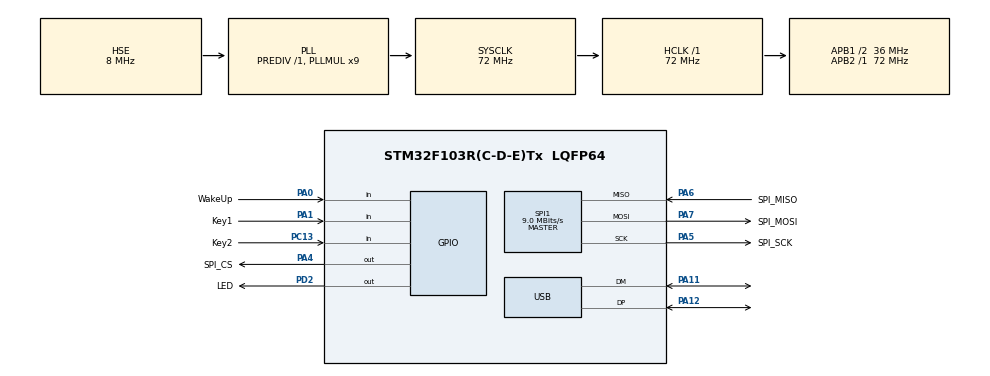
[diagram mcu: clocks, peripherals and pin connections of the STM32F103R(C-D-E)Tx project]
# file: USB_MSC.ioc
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Mcu.Family=STM32F1
Mcu.Name=STM32F103R(C-D-E)Tx
Mcu.Package=LQFP64
NVIC.PriorityGroup=NVIC_PRIORITYGROUP_4
NVIC.TIM6_IRQn=true\:1\:0\:true\:false\:true\:true\:true\:true
NVIC.USB_LP_CAN1_RX0_IRQn=true\:0\:0\:false\:false\:true\:false\:true\:true
PA0-WKUP.GPIO_Label=WakeUp
PA0-WKUP.GPIO_PuPd=GPIO_PULLDOWN
PA0-WKUP.Signal=GPIO_Input
PA1.GPIO_Label=Key1
PA1.GPIO_PuPd=GPIO_PULLUP
PA1.Signal=GPIO_Input
PA11.Mode=Device
PA11.Signal=USB_DM
PA12.Mode=Device
PA12.Signal=USB_DP
PA13.Mode=Serial_Wire
PA13.Signal=SYS_JTMS-SWDIO
PA14.Mode=Serial_Wire
PA14.Signal=SYS_JTCK-SWCLK
PA4.GPIO_Label=SPI_CS
PA4.GPIO_PuPd=GPIO_PULLUP
PA4.GPIO_Speed=GPIO_SPEED_FREQ_HIGH
PA4.PinState=GPIO_PIN_SET
PA4.Signal=GPIO_Output
PA5.GPIO_Label=SPI_SCK
PA5.Mode=Full_Duplex_Master
PA5.Signal=SPI1_SCK
PA6.GPIO_Label=SPI_MISO
PA6.Mode=Full_Duplex_Master
PA6.Signal=SPI1_MISO
PA7.GPIO_Label=SPI_MOSI
PA7.Mode=Full_Duplex_Master
PA7.Signal=SPI1_MOSI
PC13-TAMPER-RTC.GPIO_Label=Key2
PC13-TAMPER-RTC.GPIO_PuPd=GPIO_PULLUP
PC13-TAMPER-RTC.Signal=GPIO_Input
PD0-OSC_IN.Mode=HSE-External-Oscillator
PD0-OSC_IN.Signal=RCC_OSC_IN
PD1-OSC_OUT.Mode=HSE-External-Oscillator
PD1-OSC_OUT.Signal=RCC_OSC_OUT
PD2.GPIO_Label=LED
PD2.GPIO_PuPd=GPIO_PULLUP
PD2.GPIO_Speed=GPIO_SPEED_FREQ_HIGH
PD2.PinState=GPIO_PIN_SET
PD2.Signal=GPIO_Output
ProjectManager.HeapSize=0x200
ProjectManager.StackSize=0x400
ProjectManager.TargetToolchain=MDK-ARM V5.32
RCC.AHBFreq_Value=72000000
RCC.APB1CLKDivider=RCC_HCLK_DIV2
RCC.APB1Freq_Value=36000000
RCC.APB1TimFreq_Value=72000000
RCC.APB2Freq_Value=72000000
RCC.APB2TimFreq_Value=72000000
RCC.HCLKFreq_Value=72000000
RCC.PLLMUL=RCC_PLL_MUL9
RCC.SYSCLKFreq_VALUE=72000000
RCC.SYSCLKSource=RCC_SYSCLKSOURCE_PLLCLK
RCC.USBFreq_Value=48000000
RCC.USBPrescaler=RCC_USBCLKSOURCE_PLL_DIV1_5
SPI1.BaudRatePrescaler=SPI_BAUDRATEPRESCALER_8
SPI1.CalculateBaudRate=9.0 MBits/s
SPI1.Direction=SPI_DIRECTION_2LINES
SPI1.Mode=SPI_MODE_MASTER
SPI1.VirtualType=VM_MASTER
TIM6.AutoReloadPreload=TIM_AUTORELOAD_PRELOAD_ENABLE
TIM6.Period=999
TIM6.Prescaler=71
TIM6.TIM_MasterOutputTrigger=TIM_TRGO_RESET
USB_DEVICE.CLASS_NAME_FS=MSC
USB_DEVICE.VirtualMode=Msc
USB_DEVICE.VirtualModeFS=Msc_FS
VP_TIM6_VS_ClockSourceINT.Mode=Enable_Timer
VP_USB_DEVICE_VS_USB_DEVICE_MSC_FS.Mode=MSC_FS
board=custom

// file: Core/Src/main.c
/* USER CODE BEGIN Header */
/**
  ******************************************************************************
  * @file           : main.c
  * @brief          : Main program body
  ******************************************************************************
  * @attention
  *
  * Copyright (c) 2024 STMicroelectronics.
  * All rights reserved.
  *
  * This software is licensed under terms that can be found in the LICENSE file
  * in the root directory of this software component.
  * If no LICENSE file comes with this software, it is provided AS-IS.
  *
  ******************************************************************************
  */
/* USER CODE END Header */
#include "main.h"
#include "spi.h"
#include "tim.h"
#include "usb_device.h"
#include "gpio.h"

/* USER CODE BEGIN Includes */
#include "key.h"
/* USER CODE END Includes */

void SystemClock_Config(void);

int main(void)
{

  /* MCU Configuration--------------------------------------------------------*/

  /* Reset of all peripherals, Initializes the Flash interface and the Systick. */
  HAL_Init();

  /* Configure the system clock */
  SystemClock_Config();

  /* Initialize all configured peripherals */
  MX_GPIO_Init();
  MX_SPI1_Init();
  MX_USB_DEVICE_Init();
  MX_TIM6_Init();
  /* USER CODE BEGIN 2 */
  key_init();
  /* USER CODE END 2 */

  /* Infinite loop */
  while (1)
  {

    /* USER CODE BEGIN 3 */
    HAL_GPIO_TogglePin(LED_GPIO_Port, LED_Pin);
    HAL_Delay(500);

  }
  /* USER CODE END 3 */
}

void SystemClock_Config(void)
{
  RCC_OscInitTypeDef RCC_OscInitStruct = {0};
  RCC_ClkInitTypeDef RCC_ClkInitStruct = {0};
  RCC_PeriphCLKInitTypeDef PeriphClkInit = {0};

  /** Initializes the RCC Oscillators according to the specified parameters
  * in the RCC_OscInitTypeDef structure.
  */
  RCC_OscInitStruct.OscillatorType = RCC_OSCILLATORTYPE_HSE;
  RCC_OscInitStruct.HSEState = RCC_HSE_ON;
  RCC_OscInitStruct.HSEPredivValue = RCC_HSE_PREDIV_DIV1;
  RCC_OscInitStruct.HSIState = RCC_HSI_ON;
  RCC_OscInitStruct.PLL.PLLState = RCC_PLL_ON;
  RCC_OscInitStruct.PLL.PLLSource = RCC_PLLSOURCE_HSE;
  RCC_OscInitStruct.PLL.PLLMUL = RCC_PLL_MUL9;
  if (HAL_RCC_OscConfig(&RCC_OscInitStruct) != HAL_OK)
  {
    Error_Handler();
  }

  /** Initializes the CPU, AHB and APB buses clocks
  */
  RCC_ClkInitStruct.ClockType = RCC_CLOCKTYPE_HCLK|RCC_CLOCKTYPE_SYSCLK
                              |RCC_CLOCKTYPE_PCLK1|RCC_CLOCKTYPE_PCLK2;
  RCC_ClkInitStruct.SYSCLKSource = RCC_SYSCLKSOURCE_PLLCLK;
  RCC_ClkInitStruct.AHBCLKDivider = RCC_SYSCLK_DIV1;
  RCC_ClkInitStruct.APB1CLKDivider = RCC_HCLK_DIV2;
  RCC_ClkInitStruct.APB2CLKDivider = RCC_HCLK_DIV1;

  if (HAL_RCC_ClockConfig(&RCC_ClkInitStruct, FLASH_LATENCY_2) != HAL_OK)
  {
    Error_Handler();
  }
  PeriphClkInit.PeriphClockSelection = RCC_PERIPHCLK_USB;
  PeriphClkInit.UsbClockSelection = RCC_USBCLKSOURCE_PLL_DIV1_5;
  if (HAL_RCCEx_PeriphCLKConfig(&PeriphClkInit) != HAL_OK)
  {
    Error_Handler();
  }
}

void Error_Handler(void)
{
  __disable_irq();
  while (1)
  {
  }
}
